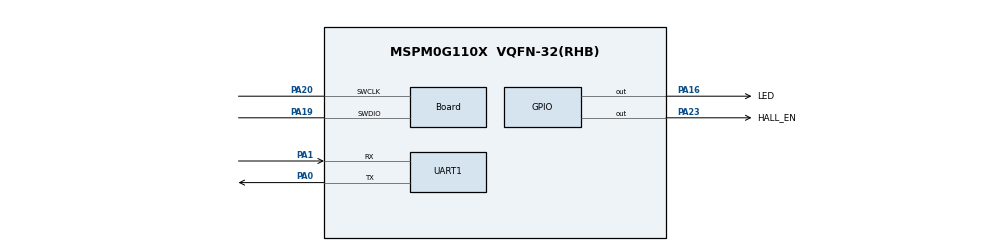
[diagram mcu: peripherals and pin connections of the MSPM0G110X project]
/**
 * @cliArgs --device "MSPM0G110X" --part "Default" --package "VQFN-32(RHB)" --product "mspm0_sdk@2.04.00.06"
 * @versions {"tool":"1.22.0+3893"}
 */

/**
 * Import the modules used in this configuration.
 */
const ADC12         = scripting.addModule("/ti/driverlib/ADC12", {}, false);
const ADC121        = ADC12.addInstance();
const GPIO          = scripting.addModule("/ti/driverlib/GPIO", {}, false);
const GPIO1         = GPIO.addInstance();
const I2C           = scripting.addModule("/ti/driverlib/I2C", {}, false);
const I2C1          = I2C.addInstance();
const SYSCTL        = scripting.addModule("/ti/driverlib/SYSCTL");
const TIMER         = scripting.addModule("/ti/driverlib/TIMER", {}, false);
const TIMER1        = TIMER.addInstance();
const TIMER2        = TIMER.addInstance();
const UART          = scripting.addModule("/ti/driverlib/UART", {}, false);
const UART1         = UART.addInstance();
const ProjectConfig = scripting.addModule("/ti/project_config/ProjectConfig");

/**
 * Write custom configuration values to the imported modules.
 */
ADC121.$name                 = "ADC12_0";
ADC121.sampClkDiv            = "DL_ADC12_CLOCK_DIVIDE_8";
ADC121.samplingOperationMode = "sequence";
ADC121.endAdd                = 1;
ADC121.adcMem1chansel        = "DL_ADC12_INPUT_CHAN_1";
ADC121.enabledInterrupts     = ["DL_ADC12_INTERRUPT_MEM0_RESULT_LOADED","DL_ADC12_INTERRUPT_MEM1_RESULT_LOADED"];
ADC121.peripheral.$assign    = "ADC0";
ADC121.adcPin0Config.$name   = "ti_driverlib_gpio_GPIOPinGeneric2";
ADC121.adcPin1Config.$name   = "ti_driverlib_gpio_GPIOPinGeneric3";

const Board                       = scripting.addModule("/ti/driverlib/Board", {}, false);
Board.peripheral.$assign          = "DEBUGSS";
Board.peripheral.swclkPin.$assign = "PA20";
Board.peripheral.swdioPin.$assign = "PA19";

GPIO1.$name                          = "GPIO_GRP_0";
GPIO1.port                           = "PORTA";
GPIO1.associatedPins.create(2);
GPIO1.associatedPins[0].assignedPin  = "16";
GPIO1.associatedPins[0].$name        = "LED";
GPIO1.associatedPins[0].initialValue = "SET";
GPIO1.associatedPins[0].pin.$assign  = "PA16";
GPIO1.associatedPins[1].$name        = "HALL_EN";
GPIO1.associatedPins[1].assignedPin  = "23";
GPIO1.associatedPins[1].initialValue = "SET";
GPIO1.associatedPins[1].pin.$assign  = "PA23";

I2C1.$name                 = "I2C_0";
I2C1.basicEnableController = true;
I2C1.sdaPinConfig.$name    = "ti_driverlib_gpio_GPIOPinGeneric4";
I2C1.sclPinConfig.$name    = "ti_driverlib_gpio_GPIOPinGeneric5";

SYSCTL.peripheral.$assign = "SYSCTL";

TIMER1.$name              = "TIMER_0";
TIMER1.timerMode          = "PERIODIC";
TIMER1.timerPeriod        = "10ms";
TIMER1.timerClkDiv        = 8;
TIMER1.interrupts         = ["ZERO"];
TIMER1.peripheral.$assign = "TIMA0";

TIMER2.$name       = "TIMER_1";
TIMER2.interrupts  = ["ZERO"];
TIMER2.timerPeriod = "0.3ms";

UART1.$name                    = "UART_0";
UART1.targetBaudRate           = 115200;
UART1.enabledInterrupts        = ["RX"];
UART1.peripheral.$assign       = "UART0";
UART1.peripheral.rxPin.$assign = "PA1";
UART1.peripheral.txPin.$assign = "PA0";
UART1.txPinConfig.$name        = "ti_driverlib_gpio_GPIOPinGeneric0";
UART1.rxPinConfig.$name        = "ti_driverlib_gpio_GPIOPinGeneric1";

ProjectConfig.migrationCondition = true;

/**
 * Pinmux solution for unlocked pins/peripherals. This ensures that minor changes to the automatic solver in a future
 * version of the tool will not impact the pinmux you originally saw.  These lines can be completely deleted in order to
 * re-solve from scratch.
 */
ADC121.peripheral.adcPin0.$suggestSolution = "PA27";
ADC121.peripheral.adcPin1.$suggestSolution = "PA26";
I2C1.peripheral.$suggestSolution           = "I2C0";
I2C1.peripheral.sdaPin.$suggestSolution    = "PA10";
I2C1.peripheral.sclPin.$suggestSolution    = "PA11";
TIMER2.peripheral.$suggestSolution         = "TIMA1";
